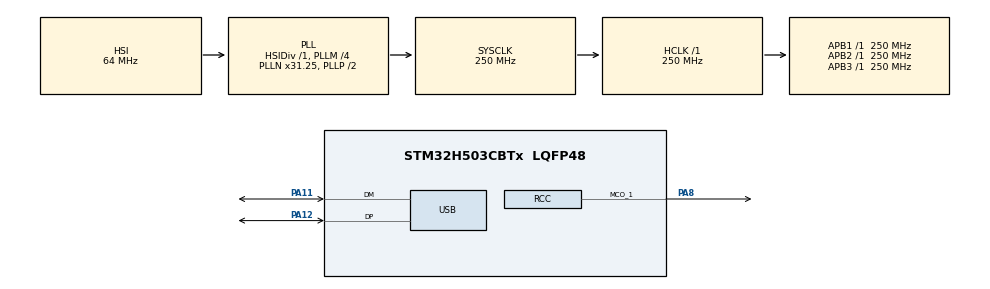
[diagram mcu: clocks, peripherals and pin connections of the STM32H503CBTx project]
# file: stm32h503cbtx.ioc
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BOOTPATH.BootPathName=LEGACY
BOOTPATH.UserSelectedBootPath=LEGACY
Mcu.Family=STM32H5
Mcu.Name=STM32H503CBTx
Mcu.Package=LQFP48
NVIC.PriorityGroup=NVIC_PRIORITYGROUP_4
NVIC.USB_DRD_FS_IRQn=true\:0\:0\:false\:false\:true\:true\:true\:true
PA11.Mode=Device
PA11.Signal=USB_DM
PA12.Mode=Device
PA12.Signal=USB_DP
PA13(JTMS/SWDIO).Mode=Serial_Wire
PA13(JTMS/SWDIO).Signal=DEBUG_JTMS-SWDIO
PA14(JTCK/SWCLK).Mode=Serial_Wire
PA14(JTCK/SWCLK).Signal=DEBUG_JTCK-SWCLK
PA8.Mode=Clock-out
PA8.Signal=RCC_MCO_1
PH0-OSC_IN(PH0).Mode=HSE-External-Oscillator
PH0-OSC_IN(PH0).Signal=RCC_OSC_IN
PH1-OSC_OUT(PH1).Mode=HSE-External-Oscillator
PH1-OSC_OUT(PH1).Signal=RCC_OSC_OUT
ProjectManager.HeapSize=0x200
ProjectManager.StackSize=0x400
ProjectManager.TargetToolchain=STM32CubeIDE
RCC.ADCFreq_Value=250000000
RCC.AHBFreq_Value=250000000
RCC.APB1Freq_Value=250000000
RCC.APB1TimFreq_Value=250000000
RCC.APB2Freq_Value=250000000
RCC.APB2TimFreq_Value=250000000
RCC.APB3Freq_Value=250000000
RCC.CSI_VALUE=4000000
RCC.CortexFreq_Value=250000000
RCC.EPOD_VALUE=64000000
RCC.HCLKFreq_Value=250000000
RCC.HSE_VALUE=8000000
RCC.HSI48_VALUE=48000000
RCC.HSIDiv=RCC_HSI_DIV1
RCC.HSI_VALUE=64000000
RCC.LSE_VALUE=32768
RCC.LSIRC_VALUE=32000
RCC.PLLFRACN=2048
RCC.PLLM=4
RCC.PLLN=31
RCC.PLLSourceVirtual=RCC_PLL1_SOURCE_HSI
RCC.RCC_MCO1Source=RCC_MCO1SOURCE_HSE
RCC.RCC_MCODiv=RCC_MCODIV_8
RCC.SYSCLKFreq_VALUE=250000000
RCC.SYSCLKSource=RCC_SYSCLKSOURCE_PLLCLK
RCC.USBFreq_Value=48000000
RCC.VCOOutputFreq_Value=500000000
USB.VirtualMode=Device_Only
USBX.BSP.number=1
USBX.Core_System=1
USBX.USBD_CDCACM_EPIN_ADDR=2
USBX.USBD_CDCACM_EPOUT_ADDR=3
USBX.USBX_DEVICE_SYS_SIZE=10*1024
USBX.UX_DEVICE_APP_MEM_POOL_SIZE_STANDALONE=10*1024
USBX.UX_DEVICE_CDC_ACM=1
USBX.UX_DEVICE_CLASS_CDC_ACM_TRANSMISSION_DISABLE=0
USBX.UX_Device_Controller=1
USBX.UX_Device_CoreStack=1
USBX0.BSP.STBoard=false
USBX0.BSP.api=Unknown
USBX0.BSP.instance=USB
USBX0.BSP.ip=USB
USBX0.BSP.mode=Device_Only
USBX0.BSP.name=USB_Device
USBX0.BSP.solution=USB
VP_BOOTPATH_VS_BOOTPATH.Mode=BP_Activate
VP_CORTEX_M33_NS_VS_Hclk.Mode=Hclk_Mode
VP_ICACHE_VS_ICACHE.Mode=DirectMappedCache
VP_MEMORYMAP_VS_MEMORYMAP.Mode=CurAppReg
VP_PWR_VS_DBSignals.Mode=DisableDeadBatterySignals
VP_PWR_VS_LPOM.Mode=PowerOptimisation
VP_PWR_VS_SECSignals.Mode=Security/Privilege
VP_RCC_USB.Mode=CRS SYNC Source USB
VP_USBX_Core_System.Mode=Core_System
VP_USBX_UX\ Device\ CDC\ ACM\ Class_FS.Mode=UX_Device_class_CDC_ACM_FS
VP_USBX_UX\ Device\ Controller_FS.Mode=UX_Device_Controller_FS
VP_USBX_UX\ Device\ CoreStack_FS.Mode=UX_Device_CoreStack_FS
board=custom

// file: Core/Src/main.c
/* USER CODE BEGIN Header */
/**
  ******************************************************************************
  * @file           : main.c
  * @brief          : Main program body
  ******************************************************************************
  * @attention
  *
  * Copyright (c) 2025 STMicroelectronics.
  * All rights reserved.
  *
  * This software is licensed under terms that can be found in the LICENSE file
  * in the root directory of this software component.
  * If no LICENSE file comes with this software, it is provided AS-IS.
  *
  ******************************************************************************
  */
/* USER CODE END Header */
#include "main.h"
#include "app_usbx_device.h"

/* USER CODE BEGIN Includes */
extern UCHAR* usbx_cdc_acm_read_process(int* Size);
extern int usbx_cdc_acm_write_process(UCHAR* msg, int Size);
/* USER CODE END Includes */

PCD_HandleTypeDef hpcd_USB_DRD_FS;

void SystemClock_Config(void);
static void MX_GPIO_Init(void);
static void MX_ICACHE_Init(void);

int main(void)
{

  /* MCU Configuration--------------------------------------------------------*/

  /* Reset of all peripherals, Initializes the Flash interface and the Systick. */
  HAL_Init();

  /* Configure the system clock */
  SystemClock_Config();

  /* Initialize all configured peripherals */
  MX_GPIO_Init();
  MX_ICACHE_Init();
  MX_USB_PCD_Init();
  MX_USBX_Device_Init();
  /* USER CODE BEGIN 2 */

  HAL_PCDEx_PMAConfig(&hpcd_USB_DRD_FS, 0x00 , PCD_SNG_BUF, 0x40);
  HAL_PCDEx_PMAConfig(&hpcd_USB_DRD_FS, 0x80 , PCD_SNG_BUF, 0x80);
  HAL_PCDEx_PMAConfig(&hpcd_USB_DRD_FS, 0x01, PCD_SNG_BUF, 0xC0);
  HAL_PCDEx_PMAConfig(&hpcd_USB_DRD_FS, 0x81, PCD_SNG_BUF, 0x100);
  HAL_PCDEx_PMAConfig(&hpcd_USB_DRD_FS, 0x82, PCD_SNG_BUF, 0x140);

  ux_dcd_stm32_initialize((ULONG)USB_DRD_FS, (ULONG)&hpcd_USB_DRD_FS);

  /* Start device USB */
  HAL_PCD_Start(&hpcd_USB_DRD_FS);
  /* USER CODE END 2 */

  /* Infinite loop */
  /* USER CODE BEGIN WHILE */
  while (1)
  {
	ux_device_stack_tasks_run();
//	int ReadSize = 0;
//	UCHAR* Buffer = usbx_cdc_acm_read_process(&ReadSize);
//	if(ReadSize>0)

	extern int Test;
	extern UCHAR RcvByte;
	if (Test)
	{
		Test = 0;
		usbx_cdc_acm_write_process(&RcvByte,1);
	}
    /* USER CODE END WHILE */

  }
}

void SystemClock_Config(void)
{
  RCC_OscInitTypeDef RCC_OscInitStruct = {0};
  RCC_ClkInitTypeDef RCC_ClkInitStruct = {0};
  RCC_CRSInitTypeDef RCC_CRSInitStruct = {0};

  /** Configure the main internal regulator output voltage
  */
  __HAL_PWR_VOLTAGESCALING_CONFIG(PWR_REGULATOR_VOLTAGE_SCALE0);

  while(!__HAL_PWR_GET_FLAG(PWR_FLAG_VOSRDY)) {}

  /** Initializes the RCC Oscillators according to the specified parameters
  * in the RCC_OscInitTypeDef structure.
  */
  RCC_OscInitStruct.OscillatorType = RCC_OSCILLATORTYPE_HSI48|RCC_OSCILLATORTYPE_HSI
                              |RCC_OSCILLATORTYPE_HSE;
  RCC_OscInitStruct.HSEState = RCC_HSE_ON;
  RCC_OscInitStruct.HSIState = RCC_HSI_ON;
  RCC_OscInitStruct.HSIDiv = RCC_HSI_DIV1;
  RCC_OscInitStruct.HSICalibrationValue = RCC_HSICALIBRATION_DEFAULT;
  RCC_OscInitStruct.HSI48State = RCC_HSI48_ON;
  RCC_OscInitStruct.PLL.PLLState = RCC_PLL_ON;
  RCC_OscInitStruct.PLL.PLLSource = RCC_PLL1_SOURCE_HSI;
  RCC_OscInitStruct.PLL.PLLM = 4;
  RCC_OscInitStruct.PLL.PLLN = 31;
  RCC_OscInitStruct.PLL.PLLP = 2;
  RCC_OscInitStruct.PLL.PLLQ = 2;
  RCC_OscInitStruct.PLL.PLLR = 2;
  RCC_OscInitStruct.PLL.PLLRGE = RCC_PLL1_VCIRANGE_3;
  RCC_OscInitStruct.PLL.PLLVCOSEL = RCC_PLL1_VCORANGE_WIDE;
  RCC_OscInitStruct.PLL.PLLFRACN = 2048;
  if (HAL_RCC_OscConfig(&RCC_OscInitStruct) != HAL_OK)
  {
    Error_Handler();
  }

  /** Initializes the CPU, AHB and APB buses clocks
  */
  RCC_ClkInitStruct.ClockType = RCC_CLOCKTYPE_HCLK|RCC_CLOCKTYPE_SYSCLK
                              |RCC_CLOCKTYPE_PCLK1|RCC_CLOCKTYPE_PCLK2
                              |RCC_CLOCKTYPE_PCLK3;
  RCC_ClkInitStruct.SYSCLKSource = RCC_SYSCLKSOURCE_PLLCLK;
  RCC_ClkInitStruct.AHBCLKDivider = RCC_SYSCLK_DIV1;
  RCC_ClkInitStruct.APB1CLKDivider = RCC_HCLK_DIV1;
  RCC_ClkInitStruct.APB2CLKDivider = RCC_HCLK_DIV1;
  RCC_ClkInitStruct.APB3CLKDivider = RCC_HCLK_DIV1;

  if (HAL_RCC_ClockConfig(&RCC_ClkInitStruct, FLASH_LATENCY_5) != HAL_OK)
  {
    Error_Handler();
  }

  /** Enable the CRS APB clock
  */
  __HAL_RCC_CRS_CLK_ENABLE();

  /** Configures CRS
  */
  RCC_CRSInitStruct.Prescaler = RCC_CRS_SYNC_DIV1;
  RCC_CRSInitStruct.Source = RCC_CRS_SYNC_SOURCE_USB;
  RCC_CRSInitStruct.Polarity = RCC_CRS_SYNC_POLARITY_RISING;
  RCC_CRSInitStruct.ReloadValue = __HAL_RCC_CRS_RELOADVALUE_CALCULATE(48000000,1000);
  RCC_CRSInitStruct.ErrorLimitValue = 34;
  RCC_CRSInitStruct.HSI48CalibrationValue = 32;

  HAL_RCCEx_CRSConfig(&RCC_CRSInitStruct);
  HAL_RCC_MCOConfig(RCC_MCO1, RCC_MCO1SOURCE_HSE, RCC_MCODIV_8);
}

static void MX_ICACHE_Init(void)
{

  /** Enable instruction cache in 1-way (direct mapped cache)
  */
  if (HAL_ICACHE_ConfigAssociativityMode(ICACHE_1WAY) != HAL_OK)
  {
    Error_Handler();
  }
  if (HAL_ICACHE_Enable() != HAL_OK)
  {
    Error_Handler();
  }

}

void MX_USB_PCD_Init(void)
{

  hpcd_USB_DRD_FS.Instance = USB_DRD_FS;
  hpcd_USB_DRD_FS.Init.dev_endpoints = 8;
  hpcd_USB_DRD_FS.Init.speed = USBD_FS_SPEED;
  hpcd_USB_DRD_FS.Init.phy_itface = PCD_PHY_EMBEDDED;
  hpcd_USB_DRD_FS.Init.Sof_enable = DISABLE;
  hpcd_USB_DRD_FS.Init.low_power_enable = DISABLE;
  hpcd_USB_DRD_FS.Init.lpm_enable = DISABLE;
  hpcd_USB_DRD_FS.Init.battery_charging_enable = DISABLE;
  hpcd_USB_DRD_FS.Init.vbus_sensing_enable = DISABLE;
  hpcd_USB_DRD_FS.Init.bulk_doublebuffer_enable = DISABLE;
  hpcd_USB_DRD_FS.Init.iso_singlebuffer_enable = DISABLE;
  if (HAL_PCD_Init(&hpcd_USB_DRD_FS) != HAL_OK)
  {
    Error_Handler();
  }

}

static void MX_GPIO_Init(void)
{
  GPIO_InitTypeDef GPIO_InitStruct = {0};

  /* GPIO Ports Clock Enable */
  __HAL_RCC_GPIOH_CLK_ENABLE();
  __HAL_RCC_GPIOA_CLK_ENABLE();

  /*Configure GPIO pin : PA8 */
  GPIO_InitStruct.Pin = GPIO_PIN_8;
  GPIO_InitStruct.Mode = GPIO_MODE_AF_PP;
  GPIO_InitStruct.Pull = GPIO_NOPULL;
  GPIO_InitStruct.Speed = GPIO_SPEED_FREQ_LOW;
  GPIO_InitStruct.Alternate = GPIO_AF0_MCO;
  HAL_GPIO_Init(GPIOA, &GPIO_InitStruct);

}

void Error_Handler(void)
{
  __disable_irq();
  while (1)
  {
  }
}
